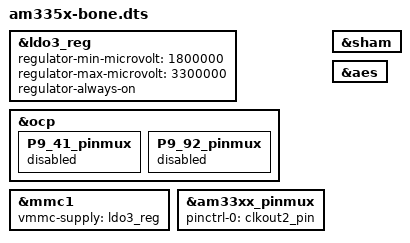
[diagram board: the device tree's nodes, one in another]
/*
 * Copyright (C) 2012 Texas Instruments Incorporated - http://www.ti.com/
 *
 * This program is free software; you can redistribute it and/or modify
 * it under the terms of the GNU General Public License version 2 as
 * published by the Free Software Foundation.
 */
/dts-v1/;

#include "am33xx.dtsi"
#include "am335x-bone-common.dtsi"
#include "am335x-bone-common-pinmux.dtsi"

&ldo3_reg {
	regulator-min-microvolt = <1800000>;
	regulator-max-microvolt = <3300000>;
	regulator-always-on;
};

&ocp {
	/* clkout2 */
	P9_41_pinmux {
		status = "disabled";
	};
	/* mmc1 */
	P9_92_pinmux {
		status = "disabled";
	};
};

&mmc1 {
	vmmc-supply = <&ldo3_reg>;
};

&am33xx_pinmux {
	pinctrl-names = "default";
	pinctrl-0 = <&clkout2_pin>;
};

&sham {
	status = "okay";
};

&aes {
	status = "okay";
};

/* spi0: */
/* P9.17 spi0_cs0 */
/* P9.18 spi0_d1 */
/* P9.21 spi0_d0 */
/* P9.22 spi0_sclk */
/* #include "am335x-bone-spi0-spidev.dtsi" */

/* spi1: */
/* P9.31 spi1_sclk */
/* P9.29 spi1_d0 */
/* P9.30 spi1_d1 */
/* P9.28 spi1_cs0 */
/* #include "am335x-bone-spi1-spidev.dtsi" */

/* spi1a: */
/* P9.42 spi1_sclk */
/* P9.29 spi1_d0 */
/* P9.30 spi1_d1 */
/* P9.20 spi1_cs0 */
/* #include "am335x-bone-spi1a-spidev.dtsi" */

/* uart1: P9.24, P9.26 */
#include "am335x-ttyO1.dtsi"
/* #include "am335x-bone-ttyO1.dtsi" */
/* uart2: P9.21, P9.22 */
#include "am335x-ttyO2.dtsi"
/* #include "am335x-bone-ttyO2.dtsi" */
/* uart4: P9.11, P9.13 */
#include "am335x-ttyO4.dtsi"
/* #include "am335x-bone-ttyO4.dtsi" */
/* uart5: P8.37, P8.38 */
#include "am335x-ttyO5.dtsi"
/* #include "am335x-bone-ttyO5.dtsi" */

/* Capes */

/* http://elinux.org/CircuitCo:Audio_Cape_RevA */
/* #include "am335x-bone-audio-reva.dtsi" */

/* http://elinux.org/CircuitCo:Audio_Cape_RevB */
/* Pins: P9.24, P9.28, P9.29, P9.31, P9.30 */
/* #include "am335x-bone-audio-revb.dtsi" */
